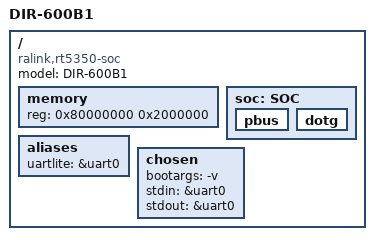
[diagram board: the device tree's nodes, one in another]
/*
 * Copyright (c) 2013, Alexander A. Mityaev <sansan@adm.ua>
 */

/dts-v1/;
/include/ "rt305x.dtsi"

/ {
	compatible = "ralink,rt5350-soc";
	model = "DIR-600B1";

	memory {
		/* 32MB RAM */
	       	device_type = "memory";
		reg = < 0x80000000 0x2000000 >;
	};


	soc: SOC {
	    pbus {
/*
		spi0 {
			flash {
				compatible = "flash,mx25l";
				spi-chipselect = <0>;
				#address-cells = <1>;
				#size-cells = <1>;

				slice@0x30000 {
	       				reg = <0x30000 0x10000>;
				        label = "config";
					read-only;
				};
			};
		};
*/
	    };
	    dotg { status = "okay"; };
	};

	aliases {
		uartlite = &uart0;
	};

	chosen {
		bootargs = "-v";
		stdin = &uart0;
		stdout = &uart0;
	};

};
